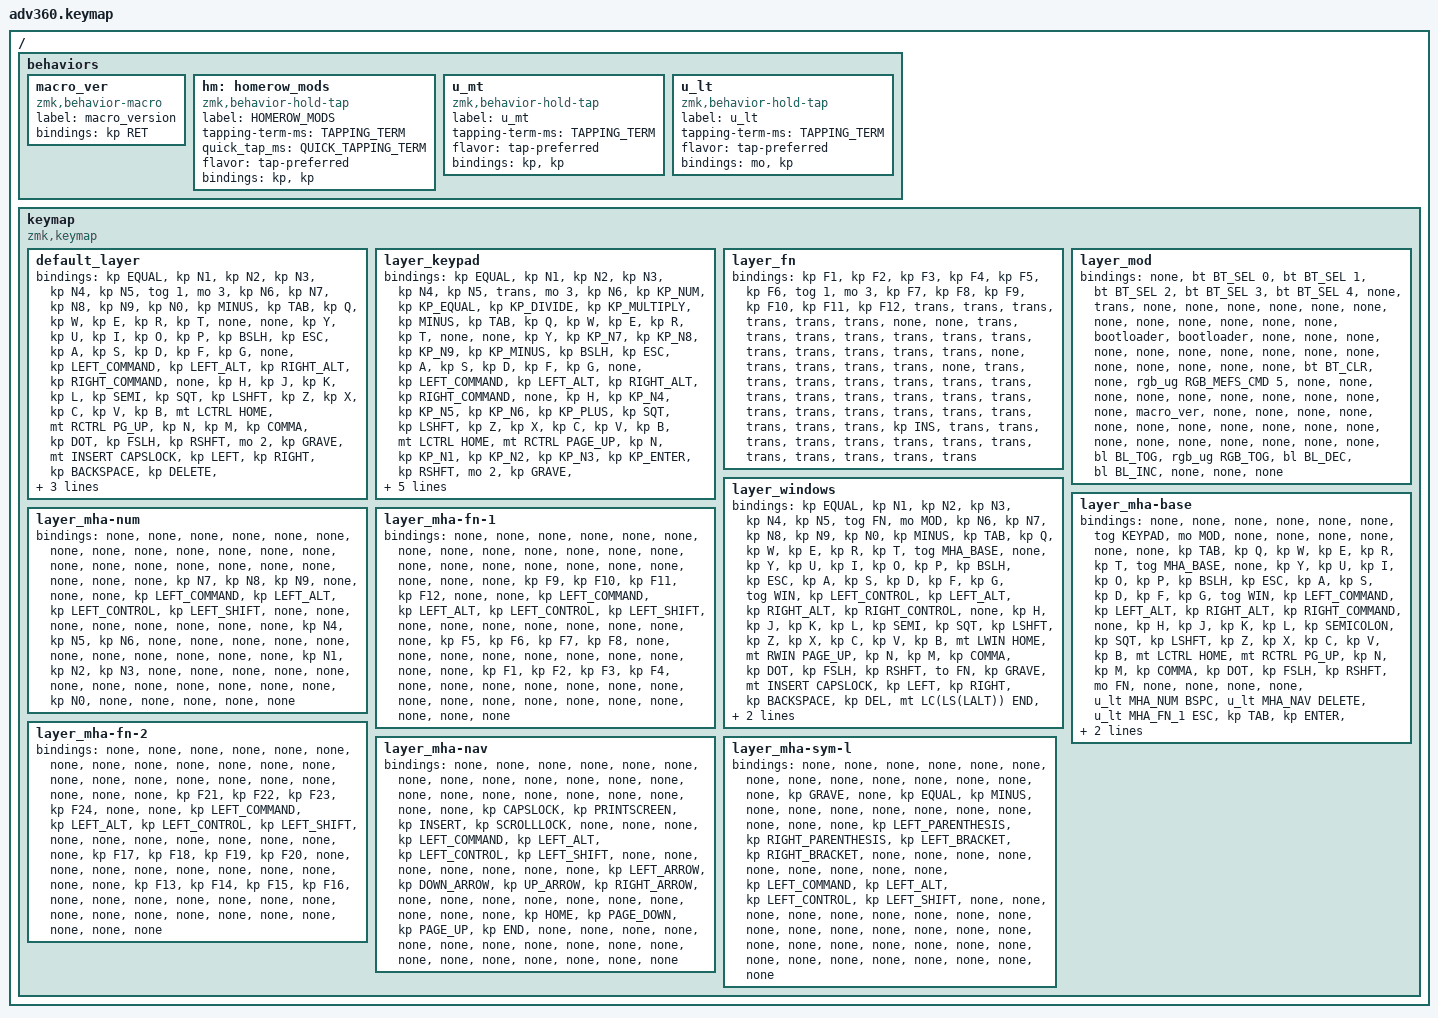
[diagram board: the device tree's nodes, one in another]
/*
 * Copyright (c) 2020 The ZMK Contributors
 *
 * SPDX-License-Identifier: MIT
 */
/* THIS FILE WAS GENERATED!
 *
 * This file was generated automatically. You may or may not want to
 * edit it directly.
 */

#include <behaviors.dtsi>
#include <dt-bindings/zmk/backlight.h>
#include <dt-bindings/zmk/bt.h>
#include <dt-bindings/zmk/keys.h>
#include <dt-bindings/zmk/rgb.h>

#define TAPPING_TERM 500
#define QUICK_TAPPING_TERM 250
#define DEFAULT 0
#define KEYPAD 1
#define FN 2
#define MOD 3
#define WIN 4
#define MHA_BASE 5
#define MHA_NUM 6
#define MHA_FN_1 7
#define MHA_FN_2 8
#define MHA_NAV 9
#define MHA_SYM_L 10

/ {
    behaviors {
      #include "macros.dtsi"
      #include "version.dtsi"
      #ifndef VERSION_MACRO
      macro_ver: macro_ver {
        compatible = "zmk,behavior-macro";
        label = "macro_version";
        #binding-cells = <0>;
        bindings = <&kp RET>;
      };
      #endif

      hm: homerow_mods {
          compatible = "zmk,behavior-hold-tap";
          label = "HOMEROW_MODS";
          #binding-cells = <2>;
          tapping-term-ms = <TAPPING_TERM>;
          quick_tap_ms = <QUICK_TAPPING_TERM>;
            flavor = "tap-preferred";
            bindings = <&kp>, <&kp>;
        };
        u_mt: u_mt {
            compatible = "zmk,behavior-hold-tap";
            label = "u_mt";
            #binding-cells = <2>;
            tapping-term-ms = <TAPPING_TERM>;
            flavor = "tap-preferred";
            bindings = <&kp>, <&kp>;
        };
        u_lt: u_lt {
            compatible = "zmk,behavior-hold-tap";
            label = "u_lt";
            #binding-cells = <2>;
            tapping-term-ms = <TAPPING_TERM>;
            flavor = "tap-preferred";
            bindings = <&mo>, <&kp>;
        };
    };

    keymap {
        compatible = "zmk,keymap";

        default_layer {
            bindings = <
            //╭────────────────────┬────────────────────┬────────────────────┬────────────────────┬────────────────────┬────────────────────┬────────────────────╮                                                                                                                                   ╭────────────────────┬────────────────────┬────────────────────┬────────────────────┬────────────────────┬────────────────────┬────────────────────╮
               &kp EQUAL            &kp N1               &kp N2               &kp N3               &kp N4               &kp N5               &tog 1                                                                                                                                                   &mo 3                &kp N6               &kp N7               &kp N8               &kp N9               &kp N0               &kp MINUS
            //├────────────────────┼────────────────────┼────────────────────┼────────────────────┼────────────────────┼────────────────────┼────────────────────┤                                                                                                                                   ├────────────────────┼────────────────────┼────────────────────┼────────────────────┼────────────────────┼────────────────────┼────────────────────┤
               &kp TAB              &kp Q                &kp W                &kp E                &kp R                &kp T                &none                                                                                                                                                    &none                &kp Y                &kp U                &kp I                &kp O                &kp P                &kp BSLH
            //├────────────────────┼────────────────────┼────────────────────┼────────────────────┼────────────────────┼────────────────────┼────────────────────┤                      ╭────────────────────┬────────────────────╮ ╭────────────────────┬────────────────────╮                      ├────────────────────┼────────────────────┼────────────────────┼────────────────────┼────────────────────┼────────────────────┼────────────────────┤
               &kp ESC              &kp A                &kp S                &kp D                &kp F                &kp G                &none                                       &kp LEFT_COMMAND     &kp LEFT_ALT           &kp RIGHT_ALT        &kp RIGHT_COMMAND                           &none                &kp H                &kp J                &kp K                &kp L                &kp SEMI             &kp SQT
            //├────────────────────┼────────────────────┼────────────────────┼────────────────────┼────────────────────┼────────────────────┼────────────────────╯ ╭────────────────────┼────────────────────┼────────────────────┤ ├────────────────────┼────────────────────┼────────────────────╮ ╰────────────────────┼────────────────────┼────────────────────┼────────────────────┼────────────────────┼────────────────────┼────────────────────┤
               &kp LSHFT            &kp Z                &kp X                &kp C                &kp V                &kp B                                                                                 &mt LCTRL HOME         &mt RCTRL PG_UP                                                                       &kp N                &kp M                &kp COMMA            &kp DOT              &kp FSLH             &kp RSHFT
            //├────────────────────┼────────────────────┼────────────────────┼────────────────────┼────────────────────┼────────────────────╯                      │                    │                    ├────────────────────┤ ├────────────────────┤                    │                    │                      ╰────────────────────┼────────────────────┼────────────────────┼────────────────────┼────────────────────┼────────────────────┤
               &mo 2                &kp GRAVE            &mt INSERT CAPSLOCK  &kp LEFT             &kp RIGHT                                                        &kp BACKSPACE        &kp DELETE           &mt LC(LS(LALT)) END  &mt RC(LS(RALT)) PG_DN  &kp ENTER          &kp SPACE                                                        &kp DOWN             &kp UP               &kp LBKT             &kp RBKT             &mo 2
            //╰────────────────────┴────────────────────┴────────────────────┴────────────────────┴────────────────────╯                                           ╰────────────────────┴────────────────────┴────────────────────╯ ╰────────────────────┴────────────────────┴────────────────────╯                                           ╰────────────────────┴────────────────────┴────────────────────┴────────────────────┴────────────────────╯
            >;
    };
    layer_keypad {
      bindings = <
            //╭────────────────────┬────────────────────┬────────────────────┬────────────────────┬────────────────────┬────────────────────┬────────────────────╮                                                                                                                                   ╭────────────────────┬────────────────────┬────────────────────┬────────────────────┬────────────────────┬────────────────────┬────────────────────╮
               &kp EQUAL            &kp N1               &kp N2               &kp N3               &kp N4               &kp N5               &trans                                                                                                                                                   &mo 3                &kp N6               &kp KP_NUM           &kp KP_EQUAL         &kp KP_DIVIDE        &kp KP_MULTIPLY      &kp MINUS
            //├────────────────────┼────────────────────┼────────────────────┼────────────────────┼────────────────────┼────────────────────┼────────────────────┤                                                                                                                                   ├────────────────────┼────────────────────┼────────────────────┼────────────────────┼────────────────────┼────────────────────┼────────────────────┤
               &kp TAB              &kp Q                &kp W                &kp E                &kp R                &kp T                &none                                                                                                                                                    &none                &kp Y                &kp KP_N7            &kp KP_N8            &kp KP_N9            &kp KP_MINUS         &kp BSLH
            //├────────────────────┼────────────────────┼────────────────────┼────────────────────┼────────────────────┼────────────────────┼────────────────────┤                      ╭────────────────────┬────────────────────╮ ╭────────────────────┬────────────────────╮                      ├────────────────────┼────────────────────┼────────────────────┼────────────────────┼────────────────────┼────────────────────┼────────────────────┤
               &kp ESC              &kp A                &kp S                &kp D                &kp F                &kp G                &none                                       &kp LEFT_COMMAND     &kp LEFT_ALT           &kp RIGHT_ALT        &kp RIGHT_COMMAND                           &none                &kp H                &kp KP_N4            &kp KP_N5            &kp KP_N6            &kp KP_PLUS          &kp SQT
            //├────────────────────┼────────────────────┼────────────────────┼────────────────────┼────────────────────┼────────────────────┼────────────────────╯ ╭────────────────────┼────────────────────┼────────────────────┤ ├────────────────────┼────────────────────┼────────────────────╮ ╰────────────────────┼────────────────────┼────────────────────┼────────────────────┼────────────────────┼────────────────────┼────────────────────┤
               &kp LSHFT            &kp Z                &kp X                &kp C                &kp V                &kp B                                                                                 &mt LCTRL HOME         &mt RCTRL PAGE_UP                                                                     &kp N                &kp KP_N1            &kp KP_N2            &kp KP_N3            &kp KP_ENTER         &kp RSHFT
            //├────────────────────┼────────────────────┼────────────────────┼────────────────────┼────────────────────┼────────────────────╯                      │                    │                    ├────────────────────┤ ├────────────────────┤                    │                    │                      ╰────────────────────┼────────────────────┼────────────────────┼────────────────────┼────────────────────┼────────────────────┤
               &mo 2                &kp GRAVE            &mt INSERT CAPSLOCK  &kp LEFT             &kp RIGHT                                                        &kp BACKSPACE        &kp DELETE           &mt LC(LS(LALT)) END  &mt RC(RS(RALT)) PG_DN  &kp ENTER          &kp KP_N0                                                        &kp UP               &kp DOWN             &kp KP_DOT           &kp RBKT             &mo 2
            //╰────────────────────┴────────────────────┴────────────────────┴────────────────────┴────────────────────╯                                           ╰────────────────────┴────────────────────┴────────────────────╯ ╰────────────────────┴────────────────────┴────────────────────╯                                           ╰────────────────────┴────────────────────┴────────────────────┴────────────────────┴────────────────────╯
      >;
    };
    layer_fn {
      bindings = <
            //╭────────────────────┬────────────────────┬────────────────────┬────────────────────┬────────────────────┬────────────────────┬────────────────────╮                                                                                                                                   ╭────────────────────┬────────────────────┬────────────────────┬────────────────────┬────────────────────┬────────────────────┬────────────────────╮
               &kp F1               &kp F2               &kp F3               &kp F4               &kp F5               &kp F6               &tog 1                                                                                                                                                   &mo 3                &kp F7               &kp F8               &kp F9               &kp F10              &kp F11              &kp F12
            //├────────────────────┼────────────────────┼────────────────────┼────────────────────┼────────────────────┼────────────────────┼────────────────────┤                                                                                                                                   ├────────────────────┼────────────────────┼────────────────────┼────────────────────┼────────────────────┼────────────────────┼────────────────────┤
               &trans               &trans               &trans               &trans               &trans               &trans               &none                                                                                                                                                    &none                &trans               &trans               &trans               &trans               &trans               &trans
            //├────────────────────┼────────────────────┼────────────────────┼────────────────────┼────────────────────┼────────────────────┼────────────────────┤                      ╭────────────────────┬────────────────────╮ ╭────────────────────┬────────────────────╮                      ├────────────────────┼────────────────────┼────────────────────┼────────────────────┼────────────────────┼────────────────────┼────────────────────┤
               &trans               &trans               &trans               &trans               &trans               &trans               &none                                       &trans               &trans                 &trans               &trans                                      &none                &trans               &trans               &trans               &trans               &trans               &trans
            //├────────────────────┼────────────────────┼────────────────────┼────────────────────┼────────────────────┼────────────────────┼────────────────────╯ ╭────────────────────┼────────────────────┼────────────────────┤ ├────────────────────┼────────────────────┼────────────────────╮ ╰────────────────────┼────────────────────┼────────────────────┼────────────────────┼────────────────────┼────────────────────┼────────────────────┤
               &trans               &trans               &trans               &trans               &trans               &trans                                                                                &trans                 &trans                                                                                &trans               &trans               &trans               &trans               &trans               &trans
            //├────────────────────┼────────────────────┼────────────────────┼────────────────────┼────────────────────┼────────────────────╯                      │                    │                    ├────────────────────┤ ├────────────────────┤                    │                    │                      ╰────────────────────┼────────────────────┼────────────────────┼────────────────────┼────────────────────┼────────────────────┤
               &trans               &trans               &kp INS              &trans               &trans                                                           &trans               &trans               &trans                 &trans               &trans               &trans                                                           &trans               &trans               &trans               &trans               &trans
            //╰────────────────────┴────────────────────┴────────────────────┴────────────────────┴────────────────────╯                                           ╰────────────────────┴────────────────────┴────────────────────╯ ╰────────────────────┴────────────────────┴────────────────────╯                                           ╰────────────────────┴────────────────────┴────────────────────┴────────────────────┴────────────────────╯
      >;
    };
    layer_mod {
      bindings = <
            //╭────────────────────┬────────────────────┬────────────────────┬────────────────────┬────────────────────┬────────────────────┬────────────────────╮                                                                                                                                   ╭────────────────────┬────────────────────┬────────────────────┬────────────────────┬────────────────────┬────────────────────┬────────────────────╮
               &none                &bt BT_SEL 0         &bt BT_SEL 1         &bt BT_SEL 2         &bt BT_SEL 3         &bt BT_SEL 4         &none                                                                                                                                                    &trans               &none                &none                &none                &none                &none                &none
            //├────────────────────┼────────────────────┼────────────────────┼────────────────────┼────────────────────┼────────────────────┼────────────────────┤                                                                                                                                   ├────────────────────┼────────────────────┼────────────────────┼────────────────────┼────────────────────┼────────────────────┼────────────────────┤
               &none                &none                &none                &none                &none                &none                &bootloader                                                                                                                                              &bootloader          &none                &none                &none                &none                &none                &none
            //├────────────────────┼────────────────────┼────────────────────┼────────────────────┼────────────────────┼────────────────────┼────────────────────┤                      ╭────────────────────┬────────────────────╮ ╭────────────────────┬────────────────────╮                      ├────────────────────┼────────────────────┼────────────────────┼────────────────────┼────────────────────┼────────────────────┼────────────────────┤
               &none                &none                &none                &none                &none                &none                &none                                       &none                &none                  &bt BT_CLR           &none                                       &rgb_ug RGB_MEFS_CMD 5 &none              &none                &none                &none                &none                &none
            //├────────────────────┼────────────────────┼────────────────────┼────────────────────┼────────────────────┼────────────────────┼────────────────────╯ ╭────────────────────┼────────────────────┼────────────────────┤ ├────────────────────┼────────────────────┼────────────────────╮ ╰────────────────────┼────────────────────┼────────────────────┼────────────────────┼────────────────────┼────────────────────┼────────────────────┤
               &none                &none                &none                &none                &macro_ver           &none                                                                                 &none                  &none                                                                                 &none                &none                &none                &none                &none                &none
            //├────────────────────┼────────────────────┼────────────────────┼────────────────────┼────────────────────┼────────────────────╯                      │                    │                    ├────────────────────┤ ├────────────────────┤                    │                    │                      ╰────────────────────┼────────────────────┼────────────────────┼────────────────────┼────────────────────┼────────────────────┤
               &none                &none                &none                &none                &none                                                            &none                &none                &none                  &none                &bl BL_TOG           &rgb_ug RGB_TOG                                                  &bl BL_DEC           &bl BL_INC           &none                &none                &none
            //╰────────────────────┴────────────────────┴────────────────────┴────────────────────┴────────────────────╯                                           ╰────────────────────┴────────────────────┴────────────────────╯ ╰────────────────────┴────────────────────┴────────────────────╯                                           ╰────────────────────┴────────────────────┴────────────────────┴────────────────────┴────────────────────╯

      >;
    };

        layer_windows {
            bindings = <
            //╭────────────────────┬────────────────────┬────────────────────┬────────────────────┬────────────────────┬────────────────────┬────────────────────╮                                                                                                                                   ╭────────────────────┬────────────────────┬────────────────────┬────────────────────┬────────────────────┬────────────────────┬────────────────────╮
               &kp EQUAL            &kp N1               &kp N2               &kp N3               &kp N4               &kp N5               &tog FN                                                                                                                                                  &mo MOD              &kp N6               &kp N7               &kp N8               &kp N9               &kp N0               &kp MINUS
            //├────────────────────┼────────────────────┼────────────────────┼────────────────────┼────────────────────┼────────────────────┼────────────────────┤                                                                                                                                   ├────────────────────┼────────────────────┼────────────────────┼────────────────────┼────────────────────┼────────────────────┼────────────────────┤
               &kp TAB              &kp Q                &kp W                &kp E                &kp R                &kp T                &tog MHA_BASE                                                                                                                                            &none                &kp Y                &kp U                &kp I                &kp O                &kp P                &kp BSLH
            //├────────────────────┼────────────────────┼────────────────────┼────────────────────┼────────────────────┼────────────────────┼────────────────────┤                      ╭────────────────────┬────────────────────╮ ╭────────────────────┬────────────────────╮                      ├────────────────────┼────────────────────┼────────────────────┼────────────────────┼────────────────────┼────────────────────┼────────────────────┤
               &kp ESC              &kp A                &kp S                &kp D                &kp F                &kp G                &tog WIN                                    &kp LEFT_CONTROL     &kp LEFT_ALT           &kp RIGHT_ALT        &kp RIGHT_CONTROL                           &none                &kp H                &kp J                &kp K                &kp L                &kp SEMI             &kp SQT
            //├────────────────────┼────────────────────┼────────────────────┼────────────────────┼────────────────────┼────────────────────┼────────────────────╯ ╭────────────────────┼────────────────────┼────────────────────┤ ├────────────────────┼────────────────────┼────────────────────╮ ╰────────────────────┼────────────────────┼────────────────────┼────────────────────┼────────────────────┼────────────────────┼────────────────────┤
               &kp LSHFT            &kp Z                &kp X                &kp C                &kp V                &kp B                                                                                 &mt LWIN HOME          &mt RWIN PAGE_UP                                                                      &kp N                &kp M                &kp COMMA            &kp DOT              &kp FSLH             &kp RSHFT
            //├────────────────────┼────────────────────┼────────────────────┼────────────────────┼────────────────────┼────────────────────╯                      │                    │                    ├────────────────────┤ ├────────────────────┤                    │                    │                      ╰────────────────────┼────────────────────┼────────────────────┼────────────────────┼────────────────────┼────────────────────┤
               &to FN               &kp GRAVE            &mt INSERT CAPSLOCK  &kp LEFT             &kp RIGHT                                                        &kp BACKSPACE        &kp DEL              &mt LC(LS(LALT)) END  &mt RC(LS(RALT)) PG_DN  &kp ENTER          &kp SPACE                                                        &kp DOWN             &kp UP               &kp LBKT             &kp RBKT             &mo FN
            //╰────────────────────┴────────────────────┴────────────────────┴────────────────────┴────────────────────╯                                           ╰────────────────────┴────────────────────┴────────────────────╯ ╰────────────────────┴────────────────────┴────────────────────╯                                           ╰────────────────────┴────────────────────┴────────────────────┴────────────────────┴────────────────────╯
            >;
        };

        layer_mha-base {
            bindings = <
            //╭────────────────────┬────────────────────┬────────────────────┬────────────────────┬────────────────────┬────────────────────┬────────────────────╮                                                                                                                                   ╭────────────────────┬────────────────────┬────────────────────┬────────────────────┬────────────────────┬────────────────────┬────────────────────╮
               &none                &none                &none                &none                &none                &none                &tog KEYPAD                                                                                                                                              &mo MOD              &none                &none                &none                &none                &none                &none
            //├────────────────────┼────────────────────┼────────────────────┼────────────────────┼────────────────────┼────────────────────┼────────────────────┤                                                                                                                                   ├────────────────────┼────────────────────┼────────────────────┼────────────────────┼────────────────────┼────────────────────┼────────────────────┤
               &kp TAB              &kp Q                &kp W                &kp E                &kp R                &kp T                &tog MHA_BASE                                                                                                                                            &none                &kp Y                &kp U                &kp I                &kp O                &kp P                &kp BSLH
            //├────────────────────┼────────────────────┼────────────────────┼────────────────────┼────────────────────┼────────────────────┼────────────────────┤                      ╭────────────────────┬────────────────────╮ ╭────────────────────┬────────────────────╮                      ├────────────────────┼────────────────────┼────────────────────┼────────────────────┼────────────────────┼────────────────────┼────────────────────┤
               &kp ESC              &kp A                &kp S                &kp D                &kp F                &kp G                &tog WIN                                    &kp LEFT_COMMAND     &kp LEFT_ALT           &kp RIGHT_ALT        &kp RIGHT_COMMAND                           &none                &kp H                &kp J                &kp K                &kp L                &kp SEMICOLON        &kp SQT
            //├────────────────────┼────────────────────┼────────────────────┼────────────────────┼────────────────────┼────────────────────┼────────────────────╯ ╭────────────────────┼────────────────────┼────────────────────┤ ├────────────────────┼────────────────────┼────────────────────╮ ╰────────────────────┼────────────────────┼────────────────────┼────────────────────┼────────────────────┼────────────────────┼────────────────────┤
               &kp LSHFT            &kp Z                &kp X                &kp C                &kp V                &kp B                                                                                 &mt LCTRL HOME         &mt RCTRL PG_UP                                                                       &kp N                &kp M                &kp COMMA            &kp DOT              &kp FSLH             &kp RSHFT
            //├────────────────────┼────────────────────┼────────────────────┼────────────────────┼────────────────────┼────────────────────╯                      │                    │                    ├────────────────────┤ ├────────────────────┤                    │                    │                      ╰────────────────────┼────────────────────┼────────────────────┼────────────────────┼────────────────────┼────────────────────┤
               &mo FN                &none                &none                &none                &none                                                            &u_lt MHA_NUM BSPC  &u_lt MHA_NAV DELETE &u_lt MHA_FN_1 ESC     &kp TAB              &kp ENTER            &u_lt MHA_SYM_L SPACE                                            &none                &none                &none                &none                &mo FN
            //╰────────────────────┴────────────────────┴────────────────────┴────────────────────┴────────────────────╯                                           ╰────────────────────┴────────────────────┴────────────────────╯ ╰────────────────────┴────────────────────┴────────────────────╯                                           ╰────────────────────┴────────────────────┴────────────────────┴────────────────────┴────────────────────╯
            >;
        };

        layer_mha-num {
            bindings = <
            //╭────────────────────┬────────────────────┬────────────────────┬────────────────────┬────────────────────┬────────────────────┬────────────────────╮                                                                                                                                   ╭────────────────────┬────────────────────┬────────────────────┬────────────────────┬────────────────────┬────────────────────┬────────────────────╮
               &none                &none                &none                &none                &none                &none                &none                                                                                                                                                    &none                &none                &none                &none                &none                &none                &none
            //├────────────────────┼────────────────────┼────────────────────┼────────────────────┼────────────────────┼────────────────────┼────────────────────┤                                                                                                                                   ├────────────────────┼────────────────────┼────────────────────┼────────────────────┼────────────────────┼────────────────────┼────────────────────┤
               &none                &none                &none                &none                &none                &none                &none                                                                                                                                                    &none                &none                &kp N7               &kp N8               &kp N9               &none                &none
            //├────────────────────┼────────────────────┼────────────────────┼────────────────────┼────────────────────┼────────────────────┼────────────────────┤                      ╭────────────────────┬────────────────────╮ ╭────────────────────┬────────────────────╮                      ├────────────────────┼────────────────────┼────────────────────┼────────────────────┼────────────────────┼────────────────────┼────────────────────┤
               &none                &kp LEFT_COMMAND     &kp LEFT_ALT         &kp LEFT_CONTROL     &kp LEFT_SHIFT       &none                &none                                       &none                &none                  &none                &none                                       &none                &none                &kp N4               &kp N5               &kp N6               &none                &none
            //├────────────────────┼────────────────────┼────────────────────┼────────────────────┼────────────────────┼────────────────────┼────────────────────╯ ╭────────────────────┼────────────────────┼────────────────────┤ ├────────────────────┼────────────────────┼────────────────────╮ ╰────────────────────┼────────────────────┼────────────────────┼────────────────────┼────────────────────┼────────────────────┼────────────────────┤
               &none                &none                &none                &none                &none                &none                                                                                 &none                  &none                                                                                 &none                &kp N1               &kp N2               &kp N3               &none                &none
            //├────────────────────┼────────────────────┼────────────────────┼────────────────────┼────────────────────┼────────────────────╯                      │                    │                    ├────────────────────┤ ├────────────────────┤                    │                    │                      ╰────────────────────┼────────────────────┼────────────────────┼────────────────────┼────────────────────┼────────────────────┤
               &none                &none                &none                &none                &none                                                            &none                &none                &none                  &none                &none                &kp N0                                                           &none                &none                &none                &none                &none
            //╰────────────────────┴────────────────────┴────────────────────┴────────────────────┴────────────────────╯                                           ╰────────────────────┴────────────────────┴────────────────────╯ ╰────────────────────┴────────────────────┴────────────────────╯                                           ╰────────────────────┴────────────────────┴────────────────────┴────────────────────┴────────────────────╯
            >;
        };

        layer_mha-fn-1 {
            bindings = <
            //╭────────────────────┬────────────────────┬────────────────────┬────────────────────┬────────────────────┬────────────────────┬────────────────────╮                                                                                                                                   ╭────────────────────┬────────────────────┬────────────────────┬────────────────────┬────────────────────┬────────────────────┬────────────────────╮
               &none                &none                &none                &none                &none                &none                &none                                                                                                                                                    &none                &none                &none                &none                &none                &none                &none
            //├────────────────────┼────────────────────┼────────────────────┼────────────────────┼────────────────────┼────────────────────┼────────────────────┤                                                                                                                                   ├────────────────────┼────────────────────┼────────────────────┼────────────────────┼────────────────────┼────────────────────┼────────────────────┤
               &none                &none                &none                &none                &none                &none                &none                                                                                                                                                    &none                &none                &kp F9               &kp F10              &kp F11              &kp F12              &none
            //├────────────────────┼────────────────────┼────────────────────┼────────────────────┼────────────────────┼────────────────────┼────────────────────┤                      ╭────────────────────┬────────────────────╮ ╭────────────────────┬────────────────────╮                      ├────────────────────┼────────────────────┼────────────────────┼────────────────────┼────────────────────┼────────────────────┼────────────────────┤
               &none                &kp LEFT_COMMAND     &kp LEFT_ALT         &kp LEFT_CONTROL     &kp LEFT_SHIFT       &none                &none                                       &none                &none                  &none                &none                                       &none                &none                &kp F5               &kp F6               &kp F7               &kp F8               &none
            //├────────────────────┼────────────────────┼────────────────────┼────────────────────┼────────────────────┼────────────────────┼────────────────────╯ ╭────────────────────┼────────────────────┼────────────────────┤ ├────────────────────┼────────────────────┼────────────────────╮ ╰────────────────────┼────────────────────┼────────────────────┼────────────────────┼────────────────────┼────────────────────┼────────────────────┤
               &none                &none                &none                &none                &none                &none                                                                                 &none                  &none                                                                                 &none                &kp F1               &kp F2               &kp F3               &kp F4               &none
            //├────────────────────┼────────────────────┼────────────────────┼────────────────────┼────────────────────┼────────────────────╯                      │                    │                    ├────────────────────┤ ├────────────────────┤                    │                    │                      ╰────────────────────┼────────────────────┼────────────────────┼────────────────────┼────────────────────┼────────────────────┤
               &none                &none                &none                &none                &none                                                            &none                &none                &none                  &none                &none                &none                                                            &none                &none                &none                &none                &none
            //╰────────────────────┴────────────────────┴────────────────────┴────────────────────┴────────────────────╯                                           ╰────────────────────┴────────────────────┴────────────────────╯ ╰────────────────────┴────────────────────┴────────────────────╯                                           ╰────────────────────┴────────────────────┴────────────────────┴────────────────────┴────────────────────╯
            >;
        };

        layer_mha-fn-2 {
            bindings = <
            //╭────────────────────┬────────────────────┬────────────────────┬────────────────────┬────────────────────┬────────────────────┬────────────────────╮                                                                                                                                   ╭────────────────────┬────────────────────┬────────────────────┬────────────────────┬────────────────────┬────────────────────┬────────────────────╮
               &none                &none                &none                &none                &none                &none                &none                                                                                                                                                    &none                &none                &none                &none                &none                &none                &none
            //├────────────────────┼────────────────────┼────────────────────┼────────────────────┼────────────────────┼────────────────────┼────────────────────┤                                                                                                                                   ├────────────────────┼────────────────────┼────────────────────┼────────────────────┼────────────────────┼────────────────────┼────────────────────┤
               &none                &none                &none                &none                &none                &none                &none                                                                                                                                                    &none                &none                &kp F21              &kp F22              &kp F23              &kp F24              &none
            //├────────────────────┼────────────────────┼────────────────────┼────────────────────┼────────────────────┼────────────────────┼────────────────────┤                      ╭────────────────────┬────────────────────╮ ╭────────────────────┬────────────────────╮                      ├────────────────────┼────────────────────┼────────────────────┼────────────────────┼────────────────────┼────────────────────┼────────────────────┤
               &none                &kp LEFT_COMMAND     &kp LEFT_ALT         &kp LEFT_CONTROL     &kp LEFT_SHIFT       &none                &none                                       &none                &none                  &none                &none                                       &none                &none                &kp F17              &kp F18              &kp F19              &kp F20              &none
            //├────────────────────┼────────────────────┼────────────────────┼────────────────────┼────────────────────┼────────────────────┼────────────────────╯ ╭────────────────────┼────────────────────┼────────────────────┤ ├────────────────────┼────────────────────┼────────────────────╮ ╰────────────────────┼────────────────────┼────────────────────┼────────────────────┼────────────────────┼────────────────────┼────────────────────┤
               &none                &none                &none                &none                &none                &none                                                                                 &none                  &none                                                                                 &none                &kp F13              &kp F14              &kp F15              &kp F16              &none
            //├────────────────────┼────────────────────┼────────────────────┼────────────────────┼────────────────────┼────────────────────╯                      │                    │                    ├────────────────────┤ ├────────────────────┤                    │                    │                      ╰────────────────────┼────────────────────┼────────────────────┼────────────────────┼────────────────────┼────────────────────┤
               &none                &none                &none                &none                &none                                                            &none                &none                &none                  &none                &none                &none                                                            &none                &none                &none                &none                &none
            //╰────────────────────┴────────────────────┴────────────────────┴────────────────────┴────────────────────╯                                           ╰────────────────────┴────────────────────┴────────────────────╯ ╰────────────────────┴────────────────────┴────────────────────╯                                           ╰────────────────────┴────────────────────┴────────────────────┴────────────────────┴────────────────────╯
            >;
        };

        layer_mha-nav {
            bindings = <
            //╭────────────────────┬────────────────────┬────────────────────┬────────────────────┬────────────────────┬────────────────────┬────────────────────╮                                                                                                                                   ╭────────────────────┬────────────────────┬────────────────────┬────────────────────┬────────────────────┬────────────────────┬────────────────────╮
               &none                &none                &none                &none                &none                &none                &none                                                                                                                                                    &none                &none                &none                &none                &none                &none                &none
            //├────────────────────┼────────────────────┼────────────────────┼────────────────────┼────────────────────┼────────────────────┼────────────────────┤                                                                                                                                   ├────────────────────┼────────────────────┼────────────────────┼────────────────────┼────────────────────┼────────────────────┼────────────────────┤
               &none                &none                &none                &none                &none                &none                &none                                                                                                                                                    &none                &kp CAPSLOCK         &kp PRINTSCREEN      &kp INSERT           &kp SCROLLLOCK       &none                &none
            //├────────────────────┼────────────────────┼────────────────────┼────────────────────┼────────────────────┼────────────────────┼────────────────────┤                      ╭────────────────────┬────────────────────╮ ╭────────────────────┬────────────────────╮                      ├────────────────────┼────────────────────┼────────────────────┼────────────────────┼────────────────────┼────────────────────┼────────────────────┤
               &none                &kp LEFT_COMMAND     &kp LEFT_ALT         &kp LEFT_CONTROL     &kp LEFT_SHIFT       &none                &none                                       &none                &none                  &none                &none                                       &none                &kp LEFT_ARROW       &kp DOWN_ARROW       &kp UP_ARROW         &kp RIGHT_ARROW       &none                &none
            //├────────────────────┼────────────────────┼────────────────────┼────────────────────┼────────────────────┼────────────────────┼────────────────────╯ ╭────────────────────┼────────────────────┼────────────────────┤ ├────────────────────┼────────────────────┼────────────────────╮ ╰────────────────────┼────────────────────┼────────────────────┼────────────────────┼────────────────────┼────────────────────┼────────────────────┤
               &none                &none                &none                &none                &none                &none                                                                                 &none                  &none                                                                                 &kp HOME             &kp PAGE_DOWN        &kp PAGE_UP          &kp END              &none                &none
            //├────────────────────┼────────────────────┼────────────────────┼────────────────────┼────────────────────┼────────────────────╯                      │                    │                    ├────────────────────┤ ├────────────────────┤                    │                    │                      ╰────────────────────┼────────────────────┼────────────────────┼────────────────────┼────────────────────┼────────────────────┤
               &none                &none                &none                &none                &none                                                            &none                &none                &none                  &none                &none                &none                                                            &none                &none                &none                &none                &none
            //╰────────────────────┴────────────────────┴────────────────────┴────────────────────┴────────────────────╯                                           ╰────────────────────┴────────────────────┴────────────────────╯ ╰────────────────────┴────────────────────┴────────────────────╯                                           ╰────────────────────┴────────────────────┴────────────────────┴────────────────────┴────────────────────╯
            >;
        };

        layer_mha-sym-l {
            bindings = <
            //╭────────────────────┬────────────────────┬────────────────────┬────────────────────┬────────────────────┬────────────────────┬────────────────────╮                                                                                                                                   ╭────────────────────┬────────────────────┬────────────────────┬────────────────────┬────────────────────┬────────────────────┬────────────────────╮
               &none                &none                &none                &none                &none                &none                &none                                                                                                                                                    &none                &none                &none                &none                &none                &none                &none
            //├────────────────────┼────────────────────┼────────────────────┼────────────────────┼────────────────────┼────────────────────┼────────────────────┤                                                                                                                                   ├────────────────────┼────────────────────┼────────────────────┼────────────────────┼────────────────────┼────────────────────┼────────────────────┤
               &kp GRAVE            &none                &kp EQUAL            &kp MINUS            &none                &none                &none                                                                                                                                                    &none                &none                &none                &none                &none                &none                &none
            //├────────────────────┼────────────────────┼────────────────────┼────────────────────┼────────────────────┼────────────────────┼────────────────────┤                      ╭────────────────────┬────────────────────╮ ╭────────────────────┬────────────────────╮                      ├────────────────────┼────────────────────┼────────────────────┼────────────────────┼────────────────────┼────────────────────┼────────────────────┤
               &kp LEFT_PARENTHESIS &kp RIGHT_PARENTHESIS &kp LEFT_BRACKET    &kp RIGHT_BRACKET    &none                &none                &none                                       &none                &none                  &none                &none                                       &none                &none                &kp LEFT_COMMAND     &kp LEFT_ALT         &kp LEFT_CONTROL     &kp LEFT_SHIFT       &none
            //├────────────────────┼────────────────────┼────────────────────┼────────────────────┼────────────────────┼────────────────────┼────────────────────╯ ╭────────────────────┼────────────────────┼────────────────────┤ ├────────────────────┼────────────────────┼────────────────────╮ ╰────────────────────┼────────────────────┼────────────────────┼────────────────────┼────────────────────┼────────────────────┼────────────────────┤
               &none                &none                &none                &none                &none                &none                                                                                 &none                  &none                                                                                 &none                &none                &none                &none                &none                &none
            //├────────────────────┼────────────────────┼────────────────────┼────────────────────┼────────────────────┼────────────────────╯                      │                    │                    ├────────────────────┤ ├────────────────────┤                    │                    │                      ╰────────────────────┼────────────────────┼────────────────────┼────────────────────┼────────────────────┼────────────────────┤
               &none                &none                &none                &none                &none                                                            &none                &none                &none                  &none                &none                &none                                                            &none                &none                &none                &none                &none
            //╰────────────────────┴────────────────────┴────────────────────┴────────────────────┴────────────────────╯                                           ╰────────────────────┴────────────────────┴────────────────────╯ ╰────────────────────┴────────────────────┴────────────────────╯                                           ╰────────────────────┴────────────────────┴────────────────────┴────────────────────┴────────────────────╯
            >;
        };
    };
};
